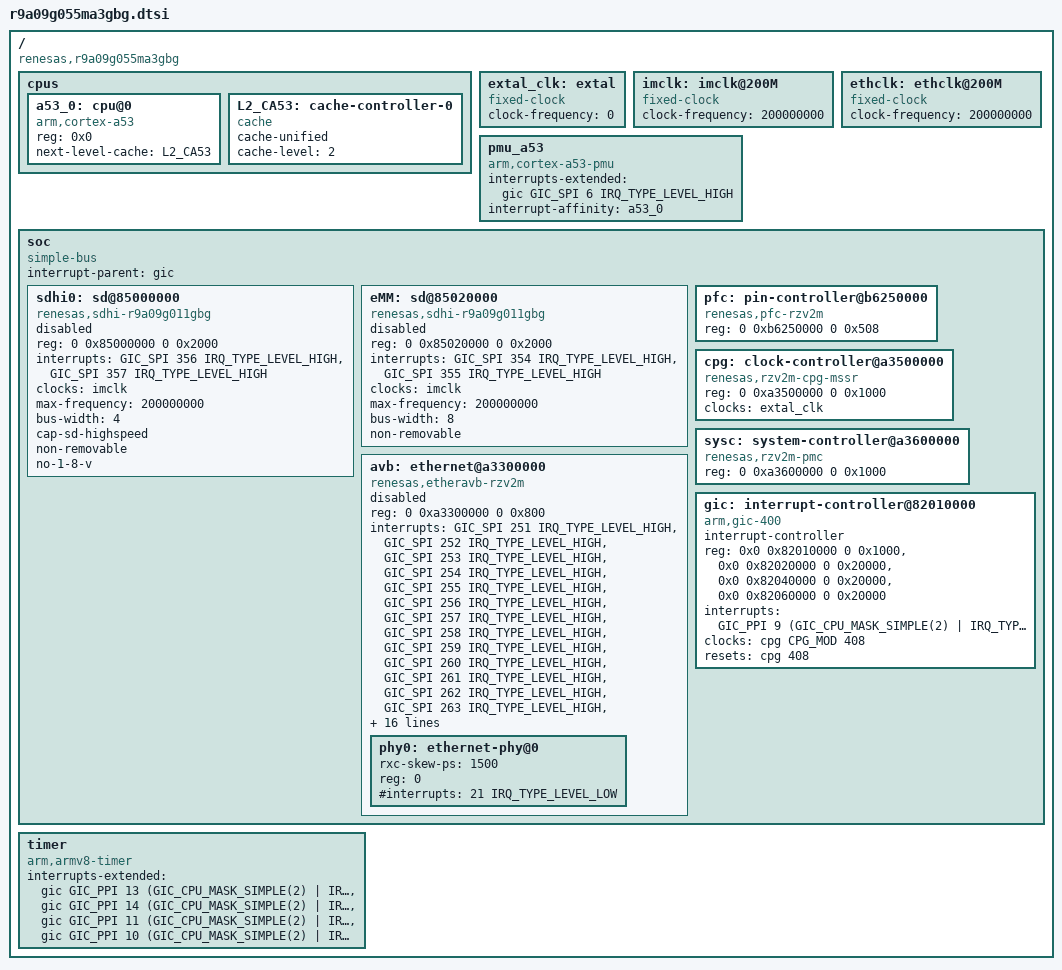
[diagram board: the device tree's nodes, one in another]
/* SPDX-License-Identifier: GPL-2.0 */
/*
 * Device Tree Source for the RZV2MA r9a09g055ma3gbg
 *
 * Copyright (C) 2022 Renesas Electronics Corp.
 */

#include <dt-bindings/clock/renesas-cpg-mssr.h>
#include <dt-bindings/interrupt-controller/arm-gic.h>

/ {
	compatible = "renesas,r9a09g055ma3gbg";
	#address-cells = <2>;
	#size-cells = <2>;

	cpus {
		#address-cells = <1>;
		#size-cells = <0>;

		a53_0: cpu@0 {
			compatible = "arm,cortex-a53", "arm,armv8";
			reg = <0x0>;
			device_type = "cpu";
			next-level-cache = <&L2_CA53>;
		};

		L2_CA53: cache-controller-0 {
			compatible = "cache";
			cache-unified;
			cache-level = <2>;
		};
	};

	extal_clk: extal {
		compatible = "fixed-clock";
		#clock-cells = <0>;
		/* This value must be overridden by the board */
		clock-frequency = <0>;
	};
	imclk: imclk@200M {
		#clock-cells = <0>;
		compatible = "fixed-clock";
		clock-frequency = <200000000>;
	};
	ethclk: ethclk@200M {
		#clock-cells = <0>;
		compatible = "fixed-clock";
		clock-frequency = <200000000>;
	};

	pmu_a53 {
		compatible = "arm,cortex-a53-pmu";
		interrupts-extended = <&gic GIC_SPI 6 IRQ_TYPE_LEVEL_HIGH>;
		interrupt-affinity = <&a53_0>;
	};

	soc: soc {
		compatible = "simple-bus";
		interrupt-parent = <&gic>;
		#address-cells = <2>;
		#size-cells = <2>;
		ranges;

		sdhi0: sd@85000000 {
			compatible = "renesas,sdhi-r9a09g011gbg",
				     "renesas,rcar-gen3-sdhi";
			reg = <0 0x85000000 0 0x2000>;
			interrupts = <GIC_SPI 356 IRQ_TYPE_LEVEL_HIGH>, <GIC_SPI 357 IRQ_TYPE_LEVEL_HIGH>;
			clocks = <&imclk>;
			max-frequency = <200000000>;
			bus-width = <4>;
			cap-sd-highspeed;
			non-removable;
			no-1-8-v;
			status = "disabled";
		};
		
		eMM: sd@85020000 {
			compatible = "renesas,sdhi-r9a09g011gbg",
				     "renesas,rcar-gen3-sdhi";
			reg = <0 0x85020000 0 0x2000>;
			interrupts = <GIC_SPI 354 IRQ_TYPE_LEVEL_HIGH>, <GIC_SPI 355 IRQ_TYPE_LEVEL_HIGH>;
			clocks = <&imclk>;
			max-frequency = <200000000>;
			bus-width = <8>;
			non-removable;
			status = "disabled";
		};

		/* PFC_base_addr = 0xB6250000 */
		pfc: pin-controller@b6250000 {
			compatible = "renesas,pfc-rzv2m";
			reg = <0 0xb6250000 0 0x508>;
		};

                /* CPG_base_addr a3500000 */
		cpg: clock-controller@a3500000 {
			compatible = "renesas,rzv2m-cpg-mssr";
			reg = <0 0xa3500000 0 0x1000>;
			clocks = <&extal_clk>;
			clock-names = "extal";
			#clock-cells = <2>;
			#power-domain-cells = <0>;
			#reset-cells = <1>;
		};

		/* PMC_base_addr a3600000 */
		sysc: system-controller@a3600000 {
			compatible = "renesas,rzv2m-pmc";
			reg = <0 0xa3600000 0 0x1000>;
			#power-domain-cells = <1>;
		};

		/* EtherAVB e6800000 */
		avb: ethernet@a3300000 {
			compatible = "renesas,etheravb-rzv2m";
			reg = <0 0xa3300000 0 0x800>;
			interrupts = <GIC_SPI 251 IRQ_TYPE_LEVEL_HIGH>,
				     <GIC_SPI 252 IRQ_TYPE_LEVEL_HIGH>,
				     <GIC_SPI 253 IRQ_TYPE_LEVEL_HIGH>,
				     <GIC_SPI 254 IRQ_TYPE_LEVEL_HIGH>,
				     <GIC_SPI 255 IRQ_TYPE_LEVEL_HIGH>,
				     <GIC_SPI 256 IRQ_TYPE_LEVEL_HIGH>,
				     <GIC_SPI 257 IRQ_TYPE_LEVEL_HIGH>,
				     <GIC_SPI 258 IRQ_TYPE_LEVEL_HIGH>,
				     <GIC_SPI 259 IRQ_TYPE_LEVEL_HIGH>,
				     <GIC_SPI 260 IRQ_TYPE_LEVEL_HIGH>,
				     <GIC_SPI 261 IRQ_TYPE_LEVEL_HIGH>,
				     <GIC_SPI 262 IRQ_TYPE_LEVEL_HIGH>,
				     <GIC_SPI 263 IRQ_TYPE_LEVEL_HIGH>,
				     <GIC_SPI 264 IRQ_TYPE_LEVEL_HIGH>,
				     <GIC_SPI 265 IRQ_TYPE_LEVEL_HIGH>,
				     <GIC_SPI 266 IRQ_TYPE_LEVEL_HIGH>,
				     <GIC_SPI 267 IRQ_TYPE_LEVEL_HIGH>,
				     <GIC_SPI 268 IRQ_TYPE_LEVEL_HIGH>,
				     <GIC_SPI 269 IRQ_TYPE_LEVEL_HIGH>,
				     <GIC_SPI 270 IRQ_TYPE_LEVEL_HIGH>,
				     <GIC_SPI 271 IRQ_TYPE_LEVEL_HIGH>,
				     <GIC_SPI 272 IRQ_TYPE_LEVEL_HIGH>,
				     <GIC_SPI 273 IRQ_TYPE_LEVEL_HIGH 
				     GIC_SPI 275 IRQ_TYPE_LEVEL_HIGH 
				     GIC_SPI 277 IRQ_TYPE_LEVEL_HIGH>,
				     <GIC_SPI 274 IRQ_TYPE_LEVEL_HIGH 
				     GIC_SPI 276 IRQ_TYPE_LEVEL_HIGH 
				     GIC_SPI 278 IRQ_TYPE_LEVEL_HIGH>,
				     <GIC_SPI 279 IRQ_TYPE_LEVEL_HIGH>;
			interrupt-names = "ch0", "ch1", "ch2", "ch3",
					  "ch4", "ch5", "ch6", "ch7",
					  "ch8", "ch9", "ch10", "ch11",
					  "ch12", "ch13", "ch14", "ch15",
					  "ch16", "ch17", "ch18", "ch19",
					  "ch20", "ch21", "ch22", "ch23",
					  "ch24";
			clocks = <&ethclk>;
			renesas,no-ether-link;
			phy-handle = <&phy0>;
			phy-mode = "gmii";
			#address-cells = <1>;
			#size-cells = <0>;
			status = "disabled";
			
			phy0: ethernet-phy@0 {
				rxc-skew-ps = <1500>;
				reg = <0>;
				#interrupts = <21 IRQ_TYPE_LEVEL_LOW>;
			};
		};

		/* GIC_GICD_base_addr 82010000 */
		gic: interrupt-controller@82010000 {
			compatible = "arm,gic-400";
			#interrupt-cells = <3>;
			#address-cells = <0>;
			interrupt-controller;
			reg = <0x0 0x82010000 0 0x1000>,
			      <0x0 0x82020000 0 0x20000>,
			      <0x0 0x82040000 0 0x20000>,
			      <0x0 0x82060000 0 0x20000>;
			interrupts = <GIC_PPI 9
					(GIC_CPU_MASK_SIMPLE(2) | IRQ_TYPE_LEVEL_HIGH)>;
			clocks = <&cpg CPG_MOD 408>;
			clock-names = "clk";
			resets = <&cpg 408>;
		};
	};

	timer {
		compatible = "arm,armv8-timer";
		interrupts-extended = <&gic GIC_PPI 13 (GIC_CPU_MASK_SIMPLE(2) | IRQ_TYPE_LEVEL_LOW)>,
				      <&gic GIC_PPI 14 (GIC_CPU_MASK_SIMPLE(2) | IRQ_TYPE_LEVEL_LOW)>,
				      <&gic GIC_PPI 11 (GIC_CPU_MASK_SIMPLE(2) | IRQ_TYPE_LEVEL_LOW)>,
				      <&gic GIC_PPI 10 (GIC_CPU_MASK_SIMPLE(2) | IRQ_TYPE_LEVEL_LOW)>;
	};
};
